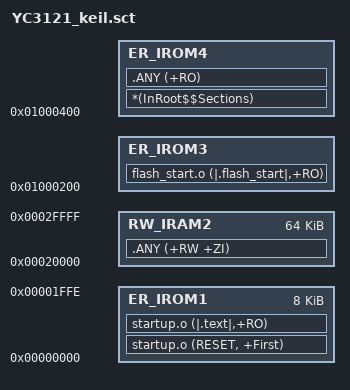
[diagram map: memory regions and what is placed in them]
; *************************************************************
; *** Scatter-Loading Description File generated by uVision ***
; *************************************************************

LR_IROM1 0x00000000 0x0001fff  {    ; load region size_region
  ER_IROM1 0x00000000 0x00001fff  {  ; load address = execution address
   startup.o (RESET, +First)
   startup.o (|.text|,+RO)
;   *(InRoot$$Sections)
  }
  ;ER_IROM2 0x4000   {
  ;rom_main.o (+RO)
  ;}
  
  ;ER_IROM3 0x100000 {
	  ;*(InRoot$$Sections)
  ;}
	
  ;ER_IROM4 0x100400   {
  ;flash_start.o (+RO)
  ;.ANY (+RO) 
  ;}
  
  ;RW_IRAM1 0x000d0000 0x0010000  {  ; RW data
   ;.ANY (+RW +ZI)
  ;}
  
;  ARM_LIB_STACK 0xE0000 EMPTY -0x10000{}
}

;LR_IROM2 0x4000 0x4000{
;	ER_IROM2 0x4000 {
;	  rom_main.o (+RO)
;	}
;}

LR_IROM3 0x1000200 0x200{
	ER_IROM3 0x1000200 {
	  flash_start.o (|.flash_start|,+RO)
	}
}

LR_IROM4 0x1000400 (0x10000-0x400){
	ER_IROM4 0x1000400 {
;	  flash_start.o (|.flash_start|,+RO)
	  *(InRoot$$Sections)
	  .ANY (+RO)
	}
	
	
	 RW_IRAM2 0x00020000 0x010000  {  ; RW data
	.ANY (+RW +ZI)
	}
}

